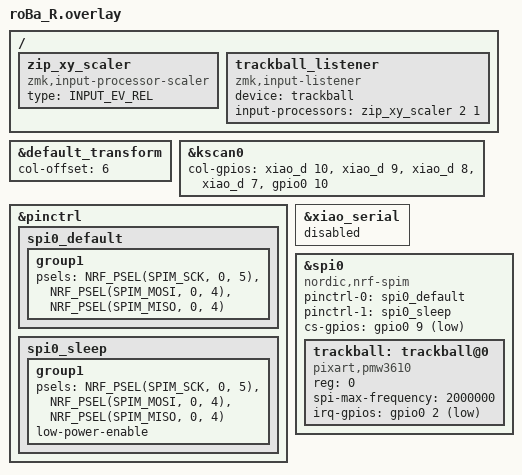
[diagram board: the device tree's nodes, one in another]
#include "roBa.dtsi"

/* --- 에러 해결을 위한 노드 정의 --- */
/ {
    /* zip_xy_scaler가 없다는 에러를 해결하기 위해 직접 정의합니다 */
    zip_xy_scaler: zip_xy_scaler {
        compatible = "zmk,input-processor-scaler";
        #input-processor-cells = <2>;
        type = <INPUT_EV_REL>;
    };

    trackball_listener {
        status = "okay";
        compatible = "zmk,input-listener";
        device = <&trackball>;
        
        /* 속도 조절: <2 1>은 2배, <3 1>은 3배입니다 */
        input-processors = <&zip_xy_scaler 2 1>;
    };
};

&default_transform {
    col-offset = <6>;
};

&kscan0 {
    col-gpios
        = <&xiao_d 10 GPIO_ACTIVE_HIGH>
        , <&xiao_d 9 GPIO_ACTIVE_HIGH>
        , <&xiao_d 8 GPIO_ACTIVE_HIGH>
        , <&xiao_d 7 GPIO_ACTIVE_HIGH>
        , <&gpio0 10 GPIO_ACTIVE_HIGH>
        ;
};

/* --- 핀 및 SPI 설정 --- */
&pinctrl {
    spi0_default: spi0_default {
        group1 {
            psels = <NRF_PSEL(SPIM_SCK, 0, 5)>,
                <NRF_PSEL(SPIM_MOSI, 0, 4)>,
                <NRF_PSEL(SPIM_MISO, 0, 4)>;
        };
    };

    spi0_sleep: spi0_sleep {
        group1 {
            psels = <NRF_PSEL(SPIM_SCK, 0, 5)>,
                <NRF_PSEL(SPIM_MOSI, 0, 4)>,
                <NRF_PSEL(SPIM_MISO, 0, 4)>;
            low-power-enable;
        };
    };
};

&xiao_serial { status = "disabled"; };

&spi0 {
    status = "okay";
    compatible = "nordic,nrf-spim";
    pinctrl-0 = <&spi0_default>;
    pinctrl-1 = <&spi0_sleep>;
    pinctrl-names = "default", "sleep";
    cs-gpios = <&gpio0 9 GPIO_ACTIVE_LOW>;

    trackball: trackball@0 {
        status = "okay";
        compatible = "pixart,pmw3610";
        reg = <0>;
        spi-max-frequency = <2000000>;
        irq-gpios = <&gpio0 2 (GPIO_ACTIVE_LOW | GPIO_PULL_UP)>;
    };
};
